# YTM32B1LE0 register map
Vendor: YTMicro; File version: 1.9
CPU: CM0PLUS r0p1, little endian, MPU, FPU, 2 interrupt priority bits
Registers are 32-bit, read-write, reset 0x0 unless marked. A register's access mark holds for its fields unless they carry their own. Offsets are from the block's base; [hi:lo] are bit positions; {n}, {i} and the like mark numbered series; 'fields as' and 'values as' point back to an identical list.

## SCU — System Clock Unit of Microcontroller
Base 0x40064000; register names take the prefix SCU_
0x00 CLKS — The register contains clock select bits.
  [1:0] CLKSRCSEL — System Clock Source selection bits.
    0=Select FIRC as system clock source; 2=Select FXOSC as system clock source; 3=Select SIRC as system clock source
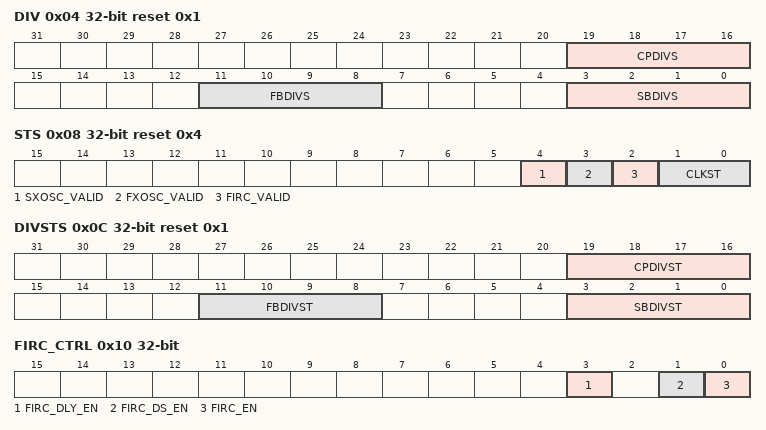
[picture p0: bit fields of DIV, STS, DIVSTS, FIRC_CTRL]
0x04 DIV reset 0x1 — System Clock Divider
  [all] fields
    {v}=Divide by {v+1} (v=0..15)
  [19:16] CPDIVS — Core Platform Clock Divider Value
  [11:8] FBDIVS — Fast Bus Clock Divider Value
  [3:0] SBDIVS — Slow Bus Clock Divider Value
0x08 STS ro reset 0x4 — System Clock Unit Status register
  [4] SXOSC_VALID rw — SXOSC Clock Valid.
    0=SXOSC Clock invalid; 1=SXOSC Clock Valid
  [3] FXOSC_VALID rw — FXOSC Clock Valid.
    0=FXOSC Clock invalid; 1=FXOSC Clock valid
  [2] FIRC_VALID rw — FIRC Clock Valid.
    0=FIRC Clock invalid; 1=FIRC Clock valid
  [1:0] CLKST rw — System Clock Source Selection status bits.
    0=FIRC is selected as system clock source; 2=FXOSC is selected as system clock source; 3=SIRC is selected as system clock source
0x0C DIVSTS ro reset 0x1 — System Clock Unit clock divider status
  [all] fields
    {v}=Divide by {v+1} (v=0..15)
  [19:16] CPDIVST rw — Core Platform Clock Divider Value
  [11:8] FBDIVST rw — Fast Bus Clock Divider Value
  [3:0] SBDIVST rw — Slow Bus Clock Divider Value
0x10 FIRC_CTRL — FIRC control register
  [3] FIRC_DLY_EN — Delay FIRC clock out.
    0=Disable FIRC clock out delay; 1=Enable FIRC clock out delay
  [1] FIRC_DS_EN — Enable FIRC when chip enters Deepsleep mode.
    0=Disable FIRC when chip enters Deepsleep mode; 1=Enable FIRC when chip enters Deepsleep mode
  [0] FIRC_EN — Enable FIRC regardless it is selected as system clock source.
    0=Disable FIRC if it is not selected as system clock source; 1=Enable FIRC regardless it is selected as system clock or not
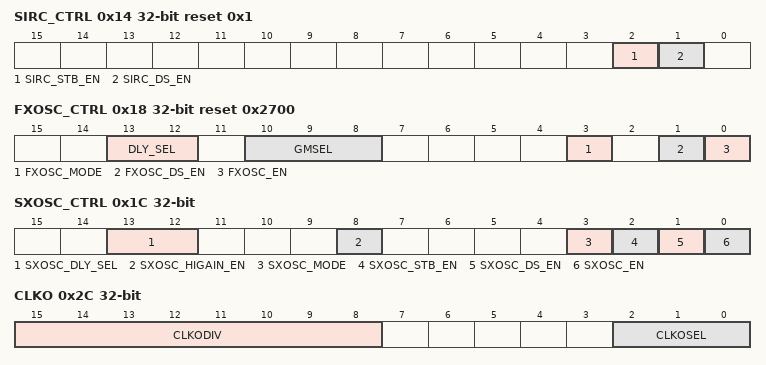
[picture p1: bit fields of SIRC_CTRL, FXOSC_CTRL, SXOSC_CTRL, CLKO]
0x14 SIRC_CTRL reset 0x1 — SIRC control register
  [2] SIRC_STB_EN — Enable SIRC when chip enters Standby mode.
    0=Disable SIRC when chip enters Standby mode; 1=Enable SIRC when chip enters Standby mode
  [1] SIRC_DS_EN — Enable SIRC when chip enters Deepsleep mode.
    0=Disable SIRC when chip enters Deepsleep mode; 1=Enable SIRC when chip enters Deepsleep mode
0x18 FXOSC_CTRL reset 0x2700 — FXOSC control register
  [13:12] DLY_SEL — FXOSC clock output delay select.
    0=4096 cycles; 1=8192 cycles; 2=16384 cycles (default); 3=32768 cycles
  [10:8] GMSEL — FXOSC Gain Select for different oscillators
    1=used for 4MHz-6MHz oscillator; 2=used for 6MHz-8MHz oscillator; 3=used for 8MHz-12MHz oscillator; 5=used for 12MHz-20MHz oscillator; 6=used for 20MHz-32MHz oscillator; 7=used for 32MHz-40MHz oscillator
  [3] FXOSC_MODE — Select FXOSC oscillator mode or bypass mode
    0=FXOSC bypass mode; 1=FXOSC oscillator mode
  [1] FXOSC_DS_EN — Enable FXOSC when chip enters Deepsleep mode.
    0=Disable FXOSC when chip enters Deepsleep mode; 1=Enable FXOSC when chip enters Deepsleep mode
  [0] FXOSC_EN — Enable Fast crystal osc regardless it is selected as system clock source.
    0=Disable FXOSC if it is not selected as system clock source; 1=Enable FXOSC regardless it is selected as system clock or not
0x1C SXOSC_CTRL — SXOSC control register
  [13:12] SXOSC_DLY_SEL — SXOSC clock output delay select.
    0=1024 cycles (default); 1=2048 cycles; 2=4096 cycles; 3=8192 cycles
  [8] SXOSC_HIGAIN_EN — Enable/Disable SXOSC High Gain
    0=Disable SXOSC High Gain; 1=Enable SXOSC High Gain
  [3] SXOSC_MODE — Select SXOSC oscillator mode or bypass mode
    0=SXOSC bypass mode; 1=SXOSC oscillator mode
  [2] SXOSC_STB_EN — Enable SXOSC when chip enters Standby mode.
    0=Disable SXOSC when chip enters Standby mode; 1=Enable SXOSC when chip enters Standby mode
  [1] SXOSC_DS_EN — Enable SXOSC when chip enters Deepsleep mode.
    0=Disable SXOSC when chip enters Deepsleep mode; 1=Enable SXOSC when chip enters Deepsleep mode
  [0] SXOSC_EN — Enable/Disable SXOSC
    0=Disable SXOSC; 1=Enable SXOSC
0x2C CLKO — Clock Output Control Register
  [15:8] CLKODIV — Clock output divider value. \begin{itemize}[label={}] \item 0b00000000 - DIV disable \item 0b00000001 - DIV disable \item 0b00000010 - DIV as the value \vspace*{-\baselineskip} \end{itemize}
  [2:0] CLKOSEL — Clock output source select
    0=None clock select to output; 1=FIRC clock output; 2=SIRC clock output; 3=FXOSC clock output; 4=SXOSC clock output; 5=LPO clock output; 7=Core clock output
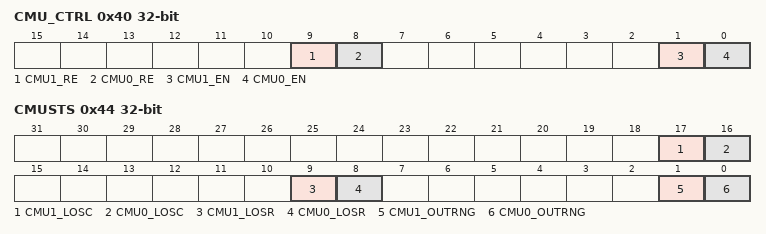
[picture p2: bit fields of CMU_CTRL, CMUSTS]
0x40 CMU_CTRL — System Clock Unit Clock Monitor Unit control register
  [9] CMU1_RE — CMU1 reset enable
    0=Reset disable when CMU event happen; 1=Reset enable when CMU event happen
  [8] CMU0_RE — CMU0 reset enable
    values as CMU1_RE
  [1] CMU1_EN — CMU1 enable
    0=CMU disable; 1=CMU enable
  [0] CMU0_EN — CMU0 enable
    0=CMU disable; 1=CMU enable
0x44 CMUSTS — System Clock Unit Clock Monitor Unit status register
  [17] CMU1_LOSC — CMU1 loss of clock
  [16] CMU0_LOSC — CMU0 loss of clock
  [9] CMU1_LOSR — CMU1 loss of reference clock
  [8] CMU0_LOSR — CMU0 loss of reference clock
  [1] CMU1_OUTRNG — CMU1 clock out of range
  [0] CMU0_OUTRNG — CMU0 clock out of range
0x48 CMUCMP0_HIGH reset 0xFFFF — System Clock Unit Clock Monitor High Comparison Value Register
  [15:0] VAL
0x4C CMUCMP0_LOW — System Clock Unit Clock Monitor Low Comparison Value Register
  [15:0] VAL
0x50 CMUCMP1_HIGH reset 0xFFFF — System Clock Unit Clock Monitor High Comparison Value Register
  [15:0] VAL
0x54 CMUCMP1_LOW — System Clock Unit Clock Monitor Low Comparison Value Register
  [15:0] VAL
